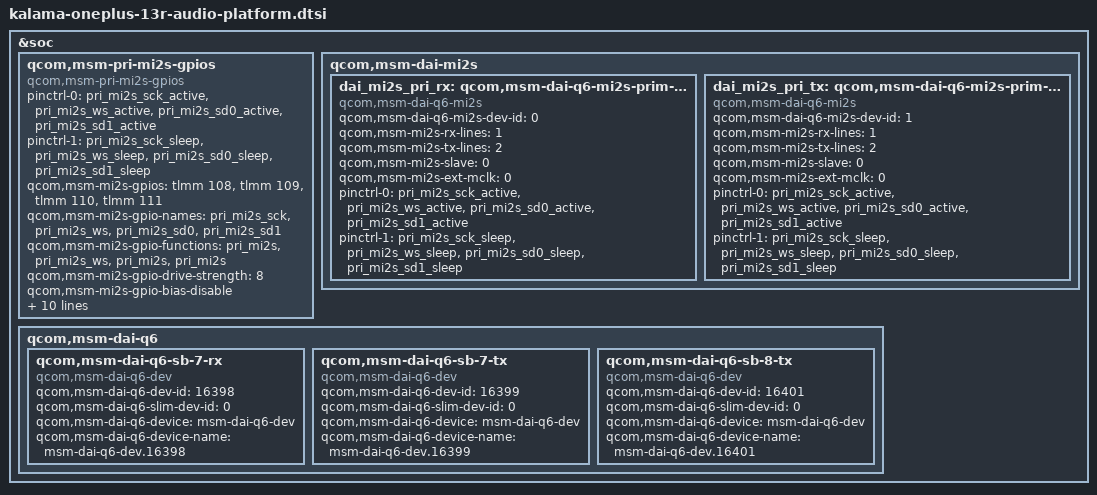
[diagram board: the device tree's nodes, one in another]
/*
 * Copyright (c) 2024, The LineageOS Project
 *
 * This program is free software; you can redistribute it and/or modify
 * it under the terms of the GNU General Public License version 2 and
 * only version 2 as published by the Free Software Foundation.
 *
 * This program is distributed in the hope that it will be useful,
 * but WITHOUT ANY WARRANTY; without even the implied warranty of
 * MERCHANTABILITY or FITNESS FOR A PARTICULAR PURPOSE.  See the
 * GNU General Public License for more details.
 */

&soc {
    qcom,msm-pri-mi2s-gpios {
        compatible = "qcom,msm-pri-mi2s-gpios";
        pinctrl-names = "default", "sleep";
        pinctrl-0 = <&pri_mi2s_sck_active &pri_mi2s_ws_active
                    &pri_mi2s_sd0_active &pri_mi2s_sd1_active>;
        pinctrl-1 = <&pri_mi2s_sck_sleep &pri_mi2s_ws_sleep
                    &pri_mi2s_sd0_sleep &pri_mi2s_sd1_sleep>;
        qcom,msm-mi2s-gpios = <&tlmm 108 0>, <&tlmm 109 0>,
                             <&tlmm 110 0>, <&tlmm 111 0>;
        qcom,msm-mi2s-gpio-names = "pri_mi2s_sck", "pri_mi2s_ws",
                                  "pri_mi2s_sd0", "pri_mi2s_sd1";
        qcom,msm-mi2s-gpio-functions = "pri_mi2s", "pri_mi2s_ws",
                                      "pri_mi2s", "pri_mi2s";
        qcom,msm-mi2s-gpio-drive-strength = <8>;
        qcom,msm-mi2s-gpio-bias-disable;
        qcom,msm-mi2s-gpio-pull-none;
        qcom,msm-mi2s-gpio-slew-rate = <0>;
        qcom,msm-mi2s-gpio-voltage-level = <1800000>;
        qcom,msm-mi2s-gpio-current-strength = <2>;
        qcom,msm-mi2s-gpio-direction = "output";
        qcom,msm-mi2s-gpio-value = <1>;
        qcom,msm-mi2s-gpio-active-high;
        qcom,msm-mi2s-gpio-push-pull;
        qcom,msm-mi2s-gpio-schmitt;
        qcom,msm-mi2s-gpio-pull-keeper;
    };

    qcom,msm-dai-mi2s {
        dai_mi2s_pri_rx: qcom,msm-dai-q6-mi2s-prim-rx {
            compatible = "qcom,msm-dai-q6-mi2s";
            qcom,msm-dai-q6-mi2s-dev-id = <0>;
            qcom,msm-mi2s-rx-lines = <1>;
            qcom,msm-mi2s-tx-lines = <2>;
            qcom,msm-mi2s-slave = <0>;
            qcom,msm-mi2s-ext-mclk = <0>;
            pinctrl-names = "default", "sleep";
            pinctrl-0 = <&pri_mi2s_sck_active &pri_mi2s_ws_active
                        &pri_mi2s_sd0_active &pri_mi2s_sd1_active>;
            pinctrl-1 = <&pri_mi2s_sck_sleep &pri_mi2s_ws_sleep
                        &pri_mi2s_sd0_sleep &pri_mi2s_sd1_sleep>;
        };

        dai_mi2s_pri_tx: qcom,msm-dai-q6-mi2s-prim-tx {
            compatible = "qcom,msm-dai-q6-mi2s";
            qcom,msm-dai-q6-mi2s-dev-id = <1>;
            qcom,msm-mi2s-rx-lines = <1>;
            qcom,msm-mi2s-tx-lines = <2>;
            qcom,msm-mi2s-slave = <0>;
            qcom,msm-mi2s-ext-mclk = <0>;
            pinctrl-names = "default", "sleep";
            pinctrl-0 = <&pri_mi2s_sck_active &pri_mi2s_ws_active
                        &pri_mi2s_sd0_active &pri_mi2s_sd1_active>;
            pinctrl-1 = <&pri_mi2s_sck_sleep &pri_mi2s_ws_sleep
                        &pri_mi2s_sd0_sleep &pri_mi2s_sd1_sleep>;
        };
    };

    qcom,msm-dai-q6 {
        qcom,msm-dai-q6-sb-7-rx {
            compatible = "qcom,msm-dai-q6-dev";
            qcom,msm-dai-q6-dev-id = <16398>;
            qcom,msm-dai-q6-slim-dev-id = <0>;
            qcom,msm-dai-q6-device = "msm-dai-q6-dev";
            qcom,msm-dai-q6-device-name = "msm-dai-q6-dev.16398";
        };

        qcom,msm-dai-q6-sb-7-tx {
            compatible = "qcom,msm-dai-q6-dev";
            qcom,msm-dai-q6-dev-id = <16399>;
            qcom,msm-dai-q6-slim-dev-id = <0>;
            qcom,msm-dai-q6-device = "msm-dai-q6-dev";
            qcom,msm-dai-q6-device-name = "msm-dai-q6-dev.16399";
        };

        qcom,msm-dai-q6-sb-8-tx {
            compatible = "qcom,msm-dai-q6-dev";
            qcom,msm-dai-q6-dev-id = <16401>;
            qcom,msm-dai-q6-slim-dev-id = <0>;
            qcom,msm-dai-q6-device = "msm-dai-q6-dev";
            qcom,msm-dai-q6-device-name = "msm-dai-q6-dev.16401";
        };
    };
}; 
